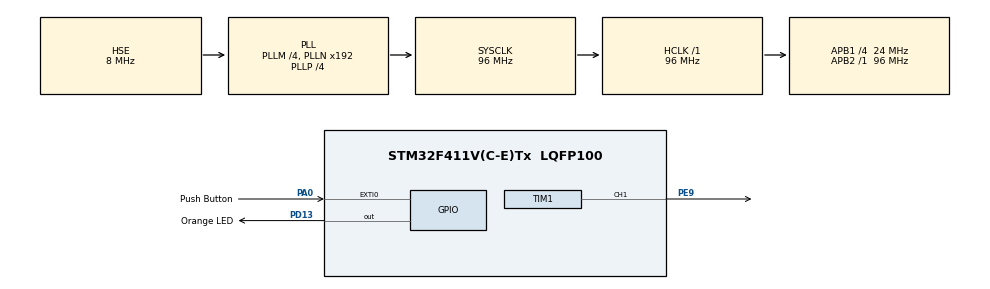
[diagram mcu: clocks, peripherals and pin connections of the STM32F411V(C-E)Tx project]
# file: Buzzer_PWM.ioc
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Mcu.Family=STM32F4
Mcu.Name=STM32F411V(C-E)Tx
Mcu.Package=LQFP100
NVIC.EXTI0_IRQn=true\:0\:0\:false\:false\:true\:true\:true
NVIC.PriorityGroup=NVIC_PRIORITYGROUP_0
PA0-WKUP.GPIO_Label=Push Button
PA0-WKUP.Signal=GPXTI0
PD13.GPIO_Label=Orange LED
PD13.Signal=GPIO_Output
PE9.Signal=S_TIM1_CH1
PH0\ -\ OSC_IN.Mode=HSE-External-Oscillator
PH0\ -\ OSC_IN.Signal=RCC_OSC_IN
PH1\ -\ OSC_OUT.Mode=HSE-External-Oscillator
PH1\ -\ OSC_OUT.Signal=RCC_OSC_OUT
ProjectManager.HeapSize=0x200
ProjectManager.StackSize=0x400
ProjectManager.TargetToolchain=MDK-ARM V5
RCC.48MHZClocksFreq_Value=48000000
RCC.AHBFreq_Value=96000000
RCC.APB1CLKDivider=RCC_HCLK_DIV4
RCC.APB1Freq_Value=24000000
RCC.APB1TimFreq_Value=48000000
RCC.APB2Freq_Value=96000000
RCC.APB2TimFreq_Value=96000000
RCC.CortexFreq_Value=96000000
RCC.HCLKFreq_Value=96000000
RCC.HSE_VALUE=8000000
RCC.HSI_VALUE=16000000
RCC.LSE_VALUE=32768
RCC.PLLI2SM=5
RCC.PLLI2SN=200
RCC.PLLM=4
RCC.PLLP=RCC_PLLP_DIV4
RCC.PLLQ=8
RCC.PLLSourceVirtual=RCC_PLLSOURCE_HSE
RCC.SYSCLKFreq_VALUE=96000000
RCC.SYSCLKSource=RCC_SYSCLKSOURCE_PLLCLK
RCC.VCOOutputFreq_Value=384000000
SH.S_TIM1_CH1.0=TIM1_CH1,PWM Generation1 CH1
TIM1.Channel-PWM\ Generation1\ CH1=TIM_CHANNEL_1
TIM1.Period=500
TIM1.Prescaler=48
TIM1.Pulse-PWM\ Generation1\ CH1=350
VP_TIM1_VS_ClockSourceINT.Mode=Internal
board=STM32F411E-DISCO

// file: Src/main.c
/* USER CODE BEGIN Header */
/**
  ******************************************************************************
  * @file           : main.c
  * @brief          : Main program body
  ******************************************************************************
  * @attention
  *
  * <h2><center>&copy; Copyright (c) 2019 STMicroelectronics.
  * All rights reserved.</center></h2>
  *
  * This software component is licensed by ST under BSD 3-Clause license,
  * the "License"; You may not use this file except in compliance with the
  * License. You may obtain a copy of the License at:
  *                        opensource.org/licenses/BSD-3-Clause
	*Buzzer driven by PWM , enabled by User Pushbutton
  *TIM1 PWM Channel 1, PE9, Prescaler 48, APB1 48MHZ, Counter period 500, Pulse 350
  *K.Kanas 23/8/2019
  ******************************************************************************
  */
/* USER CODE END Header */

#include "main.h"

TIM_HandleTypeDef htim1;

void SystemClock_Config(void);
static void MX_GPIO_Init(void);
static void MX_TIM1_Init(void);

/* USER CODE BEGIN 0 */
uint8_t state;
/* USER CODE END 0 */

int main(void)
{

  /* MCU Configuration--------------------------------------------------------*/

  /* Reset of all peripherals, Initializes the Flash interface and the Systick. */
  HAL_Init();

  /* Configure the system clock */
  SystemClock_Config();

  /* Initialize all configured peripherals */
  MX_GPIO_Init();
  MX_TIM1_Init();

  /* Infinite loop */
  while (1)
  {

  }
}

void SystemClock_Config(void)
{
  RCC_OscInitTypeDef RCC_OscInitStruct = {0};
  RCC_ClkInitTypeDef RCC_ClkInitStruct = {0};

  /** Configure the main internal regulator output voltage
  */
  __HAL_RCC_PWR_CLK_ENABLE();
  __HAL_PWR_VOLTAGESCALING_CONFIG(PWR_REGULATOR_VOLTAGE_SCALE1);
  /** Initializes the CPU, AHB and APB busses clocks
  */
  RCC_OscInitStruct.OscillatorType = RCC_OSCILLATORTYPE_HSE;
  RCC_OscInitStruct.HSEState = RCC_HSE_ON;
  RCC_OscInitStruct.PLL.PLLState = RCC_PLL_ON;
  RCC_OscInitStruct.PLL.PLLSource = RCC_PLLSOURCE_HSE;
  RCC_OscInitStruct.PLL.PLLM = 4;
  RCC_OscInitStruct.PLL.PLLN = 192;
  RCC_OscInitStruct.PLL.PLLP = RCC_PLLP_DIV4;
  RCC_OscInitStruct.PLL.PLLQ = 8;
  if (HAL_RCC_OscConfig(&RCC_OscInitStruct) != HAL_OK)
  {
    Error_Handler();
  }
  /** Initializes the CPU, AHB and APB busses clocks
  */
  RCC_ClkInitStruct.ClockType = RCC_CLOCKTYPE_HCLK|RCC_CLOCKTYPE_SYSCLK
                              |RCC_CLOCKTYPE_PCLK1|RCC_CLOCKTYPE_PCLK2;
  RCC_ClkInitStruct.SYSCLKSource = RCC_SYSCLKSOURCE_PLLCLK;
  RCC_ClkInitStruct.AHBCLKDivider = RCC_SYSCLK_DIV1;
  RCC_ClkInitStruct.APB1CLKDivider = RCC_HCLK_DIV4;
  RCC_ClkInitStruct.APB2CLKDivider = RCC_HCLK_DIV1;

  if (HAL_RCC_ClockConfig(&RCC_ClkInitStruct, FLASH_LATENCY_3) != HAL_OK)
  {
    Error_Handler();
  }
}

static void MX_TIM1_Init(void)
{

  TIM_ClockConfigTypeDef sClockSourceConfig = {0};
  TIM_MasterConfigTypeDef sMasterConfig = {0};
  TIM_OC_InitTypeDef sConfigOC = {0};
  TIM_BreakDeadTimeConfigTypeDef sBreakDeadTimeConfig = {0};

  htim1.Instance = TIM1;
  htim1.Init.Prescaler = 48;
  htim1.Init.CounterMode = TIM_COUNTERMODE_UP;
  htim1.Init.Period = 500;
  htim1.Init.ClockDivision = TIM_CLOCKDIVISION_DIV1;
  htim1.Init.RepetitionCounter = 0;
  htim1.Init.AutoReloadPreload = TIM_AUTORELOAD_PRELOAD_DISABLE;
  if (HAL_TIM_Base_Init(&htim1) != HAL_OK)
  {
    Error_Handler();
  }
  sClockSourceConfig.ClockSource = TIM_CLOCKSOURCE_INTERNAL;
  if (HAL_TIM_ConfigClockSource(&htim1, &sClockSourceConfig) != HAL_OK)
  {
    Error_Handler();
  }
  if (HAL_TIM_PWM_Init(&htim1) != HAL_OK)
  {
    Error_Handler();
  }
  sMasterConfig.MasterOutputTrigger = TIM_TRGO_RESET;
  sMasterConfig.MasterSlaveMode = TIM_MASTERSLAVEMODE_DISABLE;
  if (HAL_TIMEx_MasterConfigSynchronization(&htim1, &sMasterConfig) != HAL_OK)
  {
    Error_Handler();
  }
  sConfigOC.OCMode = TIM_OCMODE_PWM1;
  sConfigOC.Pulse = 350;
  sConfigOC.OCPolarity = TIM_OCPOLARITY_HIGH;
  sConfigOC.OCNPolarity = TIM_OCNPOLARITY_HIGH;
  sConfigOC.OCFastMode = TIM_OCFAST_DISABLE;
  sConfigOC.OCIdleState = TIM_OCIDLESTATE_RESET;
  sConfigOC.OCNIdleState = TIM_OCNIDLESTATE_RESET;
  if (HAL_TIM_PWM_ConfigChannel(&htim1, &sConfigOC, TIM_CHANNEL_1) != HAL_OK)
  {
    Error_Handler();
  }
  sBreakDeadTimeConfig.OffStateRunMode = TIM_OSSR_DISABLE;
  sBreakDeadTimeConfig.OffStateIDLEMode = TIM_OSSI_DISABLE;
  sBreakDeadTimeConfig.LockLevel = TIM_LOCKLEVEL_OFF;
  sBreakDeadTimeConfig.DeadTime = 0;
  sBreakDeadTimeConfig.BreakState = TIM_BREAK_DISABLE;
  sBreakDeadTimeConfig.BreakPolarity = TIM_BREAKPOLARITY_HIGH;
  sBreakDeadTimeConfig.AutomaticOutput = TIM_AUTOMATICOUTPUT_DISABLE;
  if (HAL_TIMEx_ConfigBreakDeadTime(&htim1, &sBreakDeadTimeConfig) != HAL_OK)
  {
    Error_Handler();
  }
  HAL_TIM_MspPostInit(&htim1);

}

static void MX_GPIO_Init(void)
{
  GPIO_InitTypeDef GPIO_InitStruct = {0};

  /* GPIO Ports Clock Enable */
  __HAL_RCC_GPIOH_CLK_ENABLE();
  __HAL_RCC_GPIOA_CLK_ENABLE();
  __HAL_RCC_GPIOE_CLK_ENABLE();
  __HAL_RCC_GPIOD_CLK_ENABLE();

  /*Configure GPIO pin Output Level */
  HAL_GPIO_WritePin(Orange_LED_GPIO_Port, Orange_LED_Pin, GPIO_PIN_RESET);

  /*Configure GPIO pin : Push_Button_Pin */
  GPIO_InitStruct.Pin = Push_Button_Pin;
  GPIO_InitStruct.Mode = GPIO_MODE_IT_RISING;
  GPIO_InitStruct.Pull = GPIO_NOPULL;
  HAL_GPIO_Init(Push_Button_GPIO_Port, &GPIO_InitStruct);

  /*Configure GPIO pin : Orange_LED_Pin */
  GPIO_InitStruct.Pin = Orange_LED_Pin;
  GPIO_InitStruct.Mode = GPIO_MODE_OUTPUT_PP;
  GPIO_InitStruct.Pull = GPIO_NOPULL;
  GPIO_InitStruct.Speed = GPIO_SPEED_FREQ_LOW;
  HAL_GPIO_Init(Orange_LED_GPIO_Port, &GPIO_InitStruct);

  /* EXTI interrupt init*/
  HAL_NVIC_SetPriority(EXTI0_IRQn, 0, 0);
  HAL_NVIC_EnableIRQ(EXTI0_IRQn);

}

/* USER CODE BEGIN 4 */

void HAL_GPIO_EXTI_Callback(uint16_t GPIO_Pin)
{
  /* Prevent unused argument(s) compilation warning */
  UNUSED(GPIO_Pin);
  /* NOTE: This function Should not be modified, when the callback is needed,
           the HAL_GPIO_EXTI_Callback could be implemented in the user file
   */

 HAL_GPIO_TogglePin(GPIOD,GPIO_PIN_13);
 state=~state;
	if(state&&(0x01)){
	  HAL_TIM_PWM_Start(&htim1,TIM_CHANNEL_1);
	  }else
	    HAL_TIM_PWM_Stop(&htim1,TIM_CHANNEL_1);
	for (uint32_t a =0;a<50000;a++){}

}

/* USER CODE END 4 */

void Error_Handler(void)
{
}

/************************ (C) COPYRIGHT STMicroelectronics *****END OF FILE****/
